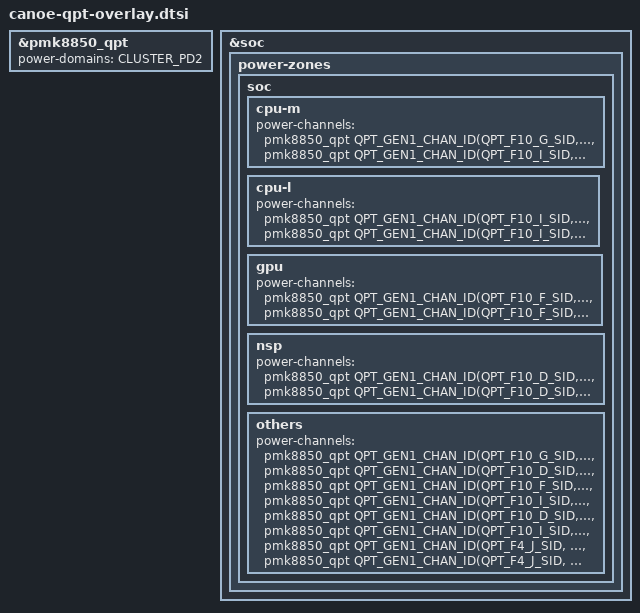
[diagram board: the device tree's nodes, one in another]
// SPDX-License-Identifier: BSD-3-Clause
/*
 * Copyright (c) 2025 Qualcomm Innovation Center, Inc. All rights reserved.
 */

#include <dt-bindings/soc/qcom,qpt-gen1-channels.h>

&pmk8850_qpt {
	status = "okay";
	power-domains = <&CLUSTER_PD2>;
};

&soc {
	power-zones {
		soc {
			cpu-m {
				power-channels =
					<&pmk8850_qpt QPT_GEN1_CHAN_ID(QPT_F10_G_SID, QPT_S10_REG)
					&pmk8850_qpt QPT_GEN1_CHAN_ID(QPT_F10_I_SID, QPT_S8_REG)>;
			};

			cpu-l {
				power-channels =
					<&pmk8850_qpt QPT_GEN1_CHAN_ID(QPT_F10_I_SID, QPT_S2_REG)
					 &pmk8850_qpt QPT_GEN1_CHAN_ID(QPT_F10_I_SID, QPT_S9_REG)>;
			};

			gpu {
				power-channels =
					<&pmk8850_qpt QPT_GEN1_CHAN_ID(QPT_F10_F_SID, QPT_S1_REG)
					&pmk8850_qpt QPT_GEN1_CHAN_ID(QPT_F10_F_SID, QPT_S10_REG)>;
			};

			nsp {
				power-channels =
					<&pmk8850_qpt QPT_GEN1_CHAN_ID(QPT_F10_D_SID, QPT_S2_REG)
					&pmk8850_qpt QPT_GEN1_CHAN_ID(QPT_F10_D_SID, QPT_S4_REG)>;
			};

			others {
				power-channels =
					<&pmk8850_qpt QPT_GEN1_CHAN_ID(QPT_F10_G_SID, QPT_S5_REG)
					&pmk8850_qpt QPT_GEN1_CHAN_ID(QPT_F10_D_SID, QPT_S7_REG)
					&pmk8850_qpt QPT_GEN1_CHAN_ID(QPT_F10_F_SID, QPT_S9_REG)
					&pmk8850_qpt QPT_GEN1_CHAN_ID(QPT_F10_I_SID, QPT_S10_REG)
					&pmk8850_qpt QPT_GEN1_CHAN_ID(QPT_F10_D_SID, QPT_S1_REG)
					&pmk8850_qpt QPT_GEN1_CHAN_ID(QPT_F10_I_SID, QPT_S1_REG)
					&pmk8850_qpt QPT_GEN1_CHAN_ID(QPT_F4_J_SID, QPT_S1_REG)
					&pmk8850_qpt QPT_GEN1_CHAN_ID(QPT_F4_J_SID, QPT_S2_REG)>;
			};
		};
	};
};
